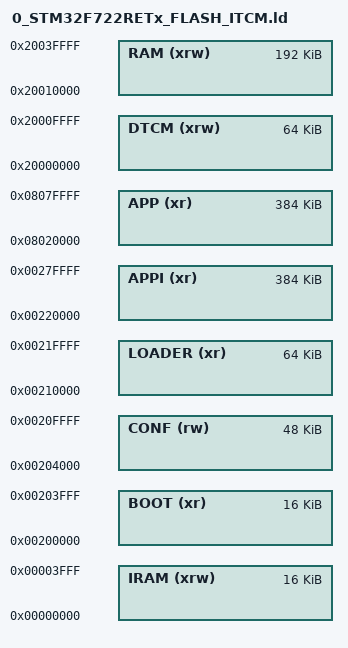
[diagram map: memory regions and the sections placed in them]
/* Specify the memory areas */
MEMORY
{
    IRAM (xrw)  : ORIGIN = 0x00000000, LENGTH = 16k
    DTCM (xrw)  : ORIGIN = 0x20000000, LENGTH = 64k
    RAM (xrw)   : ORIGIN = 0x20010000, LENGTH = 192k

    BOOT (xr)	: ORIGIN = 0x00200000, LENGTH = 16k
    CONF (rw)	: ORIGIN = 0x00204000, LENGTH = 48k
    LOADER (xr)	: ORIGIN = 0x00210000, LENGTH = 64k
    APPI (xr)	: ORIGIN = 0x00220000, LENGTH = 384k
    APP (xr)	: ORIGIN = 0x08020000, LENGTH = 384k
}

REGION_ALIAS("TEXT", APPI);
REGION_ALIAS("LOAD", APP);
